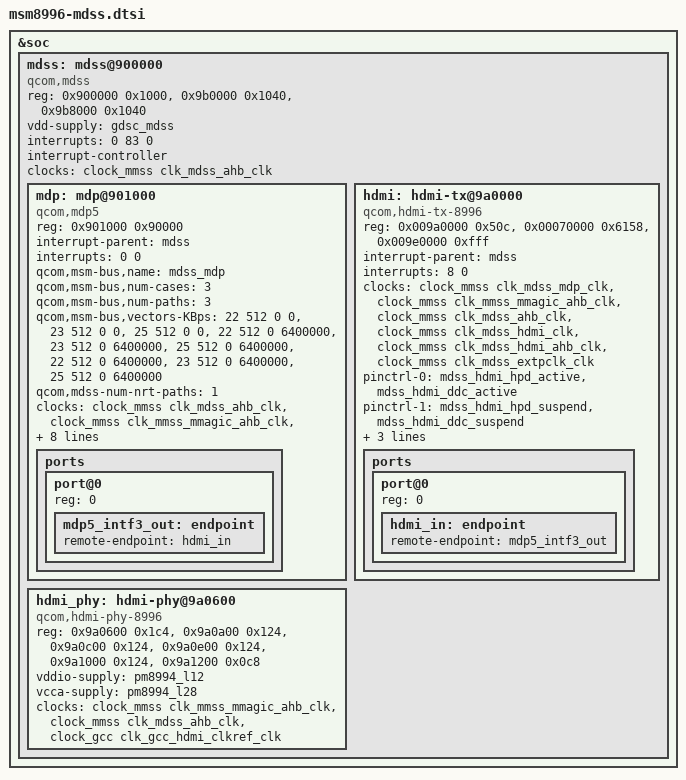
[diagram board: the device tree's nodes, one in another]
/* Copyright (c) 2014-2016, The Linux Foundation. All rights reserved.
 *
 * This program is free software; you can redistribute it and/or modify
 * it under the terms of the GNU General Public License version 2 and
 * only version 2 as published by the Free Software Foundation.
 *
 * This program is distributed in the hope that it will be useful,
 * but WITHOUT ANY WARRANTY; without even the implied warranty of
 * MERCHANTABILITY or FITNESS FOR A PARTICULAR PURPOSE.  See the
 * GNU General Public License for more details.
 */

&soc {

mdss: mdss@900000 {
			compatible = "qcom,mdss";

			reg = <0x900000 0x1000>,
			      <0x9b0000 0x1040>,
			      <0x9b8000 0x1040>;
			reg-names = "mdss_phys",
				    "vbif_phys",
				    "vbif_nrt_phys";
			vdd-supply = <&gdsc_mdss>;
			interrupts = <0 83 0>;
			interrupt-controller;
			#interrupt-cells = <1>;
			clocks = <&clock_mmss clk_mdss_ahb_clk>;
			clock-names = "iface_clk";

			#address-cells = <1>;
			#size-cells = <1>;
			ranges;

			mdp: mdp@901000 {
				compatible = "qcom,mdp5";
				reg = <0x901000 0x90000>;
				reg-names = "mdp_phys";

				interrupt-parent = <&mdss>;
				interrupts = <0 0>;
				/* Bus Scale Settings */
				qcom,msm-bus,name = "mdss_mdp";
				qcom,msm-bus,num-cases = <3>;
				qcom,msm-bus,num-paths = <3>;
				qcom,msm-bus,vectors-KBps =
					<22 512 0 0>, <23 512 0 0>, <25 512 0 0>,
					<22 512 0 6400000>, <23 512 0 6400000>, <25 512 0 6400000>,
					<22 512 0 6400000>, <23 512 0 6400000>, <25 512 0 6400000>;

				qcom,mdss-num-nrt-paths = <1>;
				clocks = <&clock_mmss clk_mdss_ahb_clk>,
					 <&clock_mmss clk_mmss_mmagic_ahb_clk>,
					 <&clock_mmss clk_mdss_axi_clk>,
					 <&clock_mmss clk_mdp_clk_src>,
					  <&clock_mmss clk_mdss_mdp_vote_clk>,
					 <&clock_mmss clk_smmu_mdp_axi_clk>,
					 <&clock_mmss clk_mdss_vsync_clk>,
					<&clock_mmss clk_mmagic_mdss_axi_clk>,
					<&clock_gcc clk_mmssnoc_axi_rpm_clk>;
				clock-names = "iface_clk",
					      "mmagic_iface_clk",
					      "bus_clk",
					      "core_clk_src",
					      "core_clk",
					      "iommu_clk",
					      "vsync_clk",
					      "mmagic_mdss_bus_clk",
					      "rpm_mmaxi_clk";
				iommus = <&mdp_smmu 0>;
				ports {
					#address-cells = <1>;
					#size-cells = <0>;

					port@0 {
						reg = <0>;
						mdp5_intf3_out: endpoint {
							remote-endpoint = <&hdmi_in>;
						};
					};
				};
			};

			hdmi: hdmi-tx@9a0000 {
				compatible = "qcom,hdmi-tx-8996";
				reg =	<0x009a0000 0x50c>,
					<0x00070000 0x6158>,
					<0x009e0000 0xfff>;
				reg-names = "core_physical",
					    "qfprom_physical",
					    "hdcp_physical";

				interrupt-parent = <&mdss>;
				interrupts = <8 0>;

				clocks = <&clock_mmss clk_mdss_mdp_clk>,
					 <&clock_mmss clk_mmss_mmagic_ahb_clk>,
					 <&clock_mmss clk_mdss_ahb_clk>,
					 <&clock_mmss clk_mdss_hdmi_clk>,
					 <&clock_mmss clk_mdss_hdmi_ahb_clk>,
					 <&clock_mmss clk_mdss_extpclk_clk>;
				clock-names =
					"mdp_core_clk",
					"mmagic_iface_clk",
					"iface_clk",
					"core_clk",
					"alt_iface_clk",
					"extp_clk";

					pinctrl-names = "default", "sleep";
	                 pinctrl-0 = <&mdss_hdmi_hpd_active &mdss_hdmi_ddc_active>;
	                 pinctrl-1 = <&mdss_hdmi_hpd_suspend &mdss_hdmi_ddc_suspend>;
					core-vdda-supply = <&pm8994_l12>;
					core-vcc-supply = <&pm8994_s4>;
				phys = <&hdmi_phy>;
				phy-names = "hdmi_phy";

				ports {
					#address-cells = <1>;
					#size-cells = <0>;

					port@0 {
						reg = <0>;
						hdmi_in: endpoint {
							remote-endpoint = <&mdp5_intf3_out>;
						};
					};
				};
			};

			hdmi_phy: hdmi-phy@9a0600 {
				compatible = "qcom,hdmi-phy-8996";
				reg = <0x9a0600 0x1c4>,
				      <0x9a0a00 0x124>,
				      <0x9a0c00 0x124>,
				      <0x9a0e00 0x124>,
				      <0x9a1000 0x124>,
				      <0x9a1200 0x0c8>;
				reg-names = "hdmi_pll",
					    "hdmi_tx_l0",
					    "hdmi_tx_l1",
					    "hdmi_tx_l2",
					    "hdmi_tx_l3",
					    "hdmi_phy";

				vddio-supply = <&pm8994_l12>;
				vcca-supply = <&pm8994_l28>;
				clocks = <&clock_mmss  clk_mmss_mmagic_ahb_clk>,
					 <&clock_mmss  clk_mdss_ahb_clk>,
					 <&clock_gcc clk_gcc_hdmi_clkref_clk>;
				clock-names = "mmagic_iface_clk",
					      "iface_clk",
						"ref_clk";
			};
		};

};
